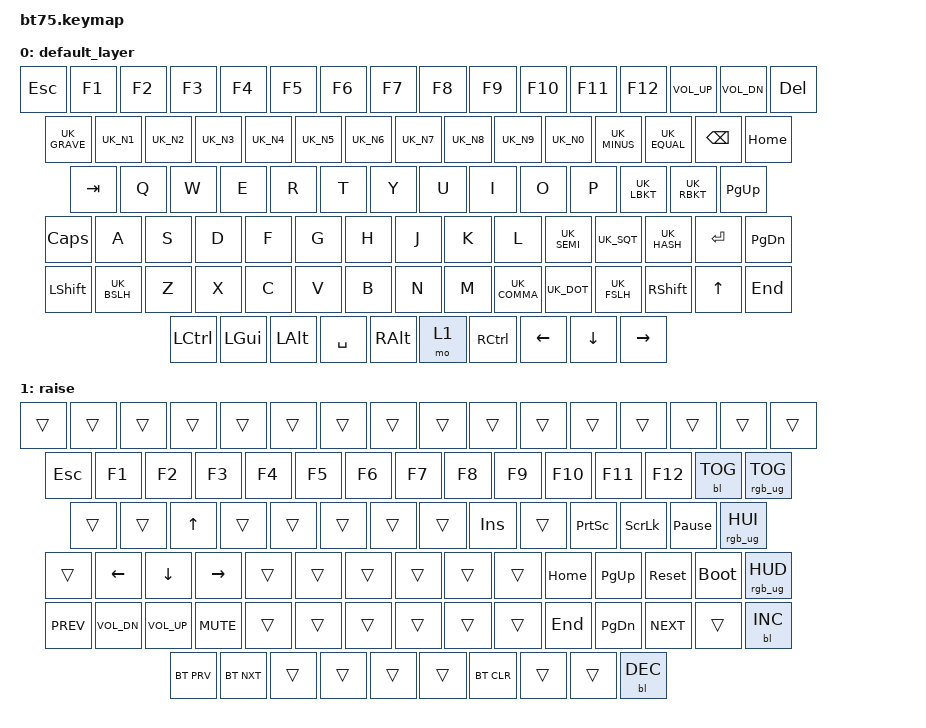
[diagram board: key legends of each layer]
#include <behaviors.dtsi>
#include <dt-bindings/zmk/keys.h>
#include <dt-bindings/zmk/bt.h>
#include <dt-bindings/zmk/rgb.h>
#include <dt-bindings/zmk/backlight.h>
#include <dt-bindings/zmk/ext_power.h>
#include "keys_uk.h"

/ {
	keymap {
		compatible = "zmk,keymap";
		default_layer {
				// ------------------------------------------------------------------------------------------------------------
				// | ESC | F1  | F2  | F3  | F4  | F5  | F6  | F7  | F9  | F9  | F10 | F11 | F12 | VOL UP | VOL DN | DEL	|
				// |  `  |  1  |  2  |  3  |  4  |  5  |  6  |  7  |  8  |  9  |  0  |  -  |  =  |   BKSP   | HOME	|
				// | TAB  |  Q  |  W  |  E  |  R  |  T  |  Y  |  U  |  I  |  O  |  P  |  [  |  ]  |        | PG UP |
				// | CAPS  |  A  |  S  |  D  |  F  |  G  |  H  |  J  |  K  |  L  |  ;  |  '  |   # | ENTER     | PG DN |
				// |  SHIFT | \   |  Z  |  X  |  C  |  V  |  B  |  N  |  M  |  ,  |  .  | /   |    SHIFT |  UP  |  END  |
				// |  CTL  |  WIN  |  ALT  |            SPACE               | ALT | 1  | CTRL |  LEFT | DOWN | RIGHT |
				// ------------------------------------------------------------------------------------------------------------
			bindings = <
				&kp ESC &kp F1 &kp F2 &kp F3 &kp F4 &kp F5 &kp F6 &kp F7 &kp  F8   &kp  F9 &kp  F10  &kp F11 &kp F12   &kp C_VOL_UP &kp C_VOL_DN &kp DEL
				&kp UK_GRAVE &kp UK_N1 &kp UK_N2 &kp UK_N3 &kp UK_N4 &kp UK_N5 &kp UK_N6 &kp UK_N7 &kp UK_N8&kp UK_N9 &kp UK_N0 &kp UK_MINUS &kp UK_EQUAL &kp BKSP &kp HOME
				&kp TAB  &kp Q  &kp W  &kp E  &kp R  &kp T  &kp Y  &kp U  &kp  I    &kp  O  &kp  P   &kp UK_LBKT &kp UK_RBKT  		 &kp PG_UP
				&kp CLCK  &kp A  &kp S  &kp D  &kp F  &kp G  &kp H  &kp J  &kp  K    &kp  L  &kp UK_SEMI &kp UK_SQT  &kp UK_HASH	&kp RET &kp PG_DN
				&kp LSHFT  &kp UK_BSLH &kp Z  &kp X  &kp C  &kp V  &kp B  &kp N  &kp M  &kp UK_COMMA &kp UK_DOT &kp UK_FSLH              &kp RSHFT &kp UP &kp END
				&kp LCTRL &kp LGUI &kp LALT            &kp SPACE                          &kp RALT  &mo 1 &kp RCTRL &kp LEFT &kp DOWN &kp RIGHT
			>;
			sensor-bindings = <&inc_dec_kp C_VOL_UP C_VOL_DN>;
		};
		raise {
			bindings = <
				&trans &trans &trans &trans &trans &trans &trans &trans &trans &trans &trans &trans &trans &trans &trans &trans
				&kp ESC &kp F1 &kp F2 &kp F3 &kp F4 &kp F5 &kp F6 &kp F7 &kp  F8   &kp  F9   &kp F10  &kp F11 &kp F12 &bl BL_TOG &rgb_ug RGB_TOG
				&trans &trans &kp UP &trans &trans &trans &trans &trans &kp INS &trans &kp PSCRN &kp SLCK &kp PAUSE_BREAK  &rgb_ug RGB_HUI
				&trans    &kp LEFT &kp DOWN &kp RIGHT &trans &trans &trans &trans &trans &trans &kp HOME  &kp PG_UP &sys_reset  &bootloader &rgb_ug RGB_HUD
				&kp C_PREV &kp C_VOL_DN &kp C_VOL_UP &kp C_MUTE &trans &trans &trans &trans &trans &trans &kp END &kp PG_DN  &kp C_NEXT &trans &bl BL_INC
				&bt BT_PRV &bt BT_NXT  &trans              &trans                            &trans   &trans  &bt BT_CLR &trans &trans &bl BL_DEC
			>;
			sensor-bindings = <&inc_dec_kp C_VOL_UP C_VOL_DN>;
		};
	};
};
